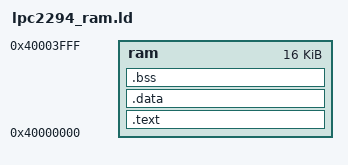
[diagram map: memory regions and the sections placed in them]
/****************************************************************************
*  Copyright (c) 2006 by Michael Fischer. All rights reserved.
*
*  Redistribution and use in source and binary forms, with or without 
*  modification, are permitted provided that the following conditions 
*  are met:
*  
*  1. Redistributions of source code must retain the above copyright 
*     notice, this list of conditions and the following disclaimer.
*  2. Redistributions in binary form must reproduce the above copyright
*     notice, this list of conditions and the following disclaimer in the 
*     documentation and/or other materials provided with the distribution.
*  3. Neither the name of the author nor the names of its contributors may 
*     be used to endorse or promote products derived from this software 
*     without specific prior written permission.
*
*  THIS SOFTWARE IS PROVIDED BY THE COPYRIGHT HOLDERS AND CONTRIBUTORS 
*  "AS IS" AND ANY EXPRESS OR IMPLIED WARRANTIES, INCLUDING, BUT NOT 
*  LIMITED TO, THE IMPLIED WARRANTIES OF MERCHANTABILITY AND FITNESS 
*  FOR A PARTICULAR PURPOSE ARE DISCLAIMED. IN NO EVENT SHALL 
*  THE COPYRIGHT OWNER OR CONTRIBUTORS BE LIABLE FOR ANY DIRECT, INDIRECT, 
*  INCIDENTAL, SPECIAL, EXEMPLARY, OR CONSEQUENTIAL DAMAGES (INCLUDING, 
*  BUT NOT LIMITED TO, PROCUREMENT OF SUBSTITUTE GOODS OR SERVICES; LOSS 
*  OF USE, DATA, OR PROFITS; OR BUSINESS INTERRUPTION) HOWEVER CAUSED 
*  AND ON ANY THEORY OF LIABILITY, WHETHER IN CONTRACT, STRICT LIABILITY, 
*  OR TORT (INCLUDING NEGLIGENCE OR OTHERWISE) ARISING IN ANY WAY OUT OF 
*  THE USE OF THIS SOFTWARE, EVEN IF ADVISED OF THE POSSIBILITY OF 
*  SUCH DAMAGE.
*
****************************************************************************
*
*  History:
*
*  31.03.06  mifi   First Version
****************************************************************************/


ENTRY(ResetHandler)
SEARCH_DIR(.)

/*
 * Define stack size here
 */
FIQ_STACK_SIZE = 0x0100;
IRQ_STACK_SIZE = 0x0100;
ABT_STACK_SIZE = 0x0100;
UND_STACK_SIZE = 0x0100;
SVC_STACK_SIZE = 0x0400;

/*
 * This file, olimex_lpce2294_ram.ld, locate the program in the internal
 * ram of the LPC2294. For more information about the memory of the LPC2294
 * take a look in the LPC2119/2129/2194/2292/2294 USER MANUAL.
 * Reference is made to the user manual from 2004 May 03
 *
 * Take a look at page 48, section 2.Memory Addressing
 */
 
MEMORY
{
  ram : org = 0x40000000, len = 16k
}

/*
 * Do not change the next code
 */
SECTIONS
{
  .text :
  {
    *(.vectors);
    . = ALIGN(4);
    *(.init);
    . = ALIGN(4);
    *(.text);
    . = ALIGN(4);
    *(.rodata);
    . = ALIGN(4);
    *(.rodata*);
    . = ALIGN(4);
    *(.glue_7t);
    . = ALIGN(4);
    *(.glue_7);
    . = ALIGN(4);
    etext = .;
  } > ram

  .data :
  {
    PROVIDE (__data_start = .);
    *(.data)
    . = ALIGN(4);
    edata = .;
    _edata = .;
    PROVIDE (__data_end = .);
  } > ram

  .bss :
  {
    PROVIDE (__bss_start = .);
    *(.bss)
    *(COMMON)
    . = ALIGN(4);
    PROVIDE (__bss_end = .);
    
    . = ALIGN(256);
    
    PROVIDE (__stack_start = .);
    
    PROVIDE (__stack_fiq_start = .);
    . += FIQ_STACK_SIZE;
    . = ALIGN(4);
    PROVIDE (__stack_fiq_end = .);

    PROVIDE (__stack_irq_start = .);
    . += IRQ_STACK_SIZE;
    . = ALIGN(4);
    PROVIDE (__stack_irq_end = .);

    PROVIDE (__stack_abt_start = .);
    . += ABT_STACK_SIZE;
    . = ALIGN(4);
    PROVIDE (__stack_abt_end = .);

    PROVIDE (__stack_und_start = .);
    . += UND_STACK_SIZE;
    . = ALIGN(4);
    PROVIDE (__stack_und_end = .);

    PROVIDE (__stack_svc_start = .);
    . += SVC_STACK_SIZE;
    . = ALIGN(4);
    PROVIDE (__stack_svc_end = .);
    PROVIDE (__stack_end = .);
    PROVIDE (__heap_start = .);   
  } > ram
    
}
/*** EOF ***/
